# V32F20x_CM33 register map
File version: 1.0.3
CPU: CM33 r0p4, little endian, MPU, FPU, DSP, 3 interrupt priority bits, 8 SAU regions
Registers are 32-bit, read-write, reset 0x0 unless marked. A register's access mark holds for its fields unless they carry their own. Offsets are from the block's base; [hi:lo] are bit positions; {n}, {i} and the like mark numbered series; 'fields as' and 'values as' point back to an identical list.

## SCR — SCR Peripheral Interface
Base 0x40070000
Same registers: SEC_SCR 0x50070000
0x00 APB0PPC_SEC — APB0PPC security configuration register.
  [31:0] SEC — This register is used to control secure access mode for each module
0x04 APB0PPC_AP — APB0PPC access privilege configuration register.
  [31:0] AP — This register is used to control privilege access mode for each module
0x08 APB0PPC_RESP — APB0PPC security violation response configuration register
  [0] RESP — APBPPC in CM33 system security violation response configuration
0x0C APB0PPC_SEC1 — APB0PPC security configuration 1 register.
  fields as APB0PPC_SEC
0x10 APB0PPC_AP1 — APB0PPC access privilege configuration 1 register.
  fields as APB0PPC_AP
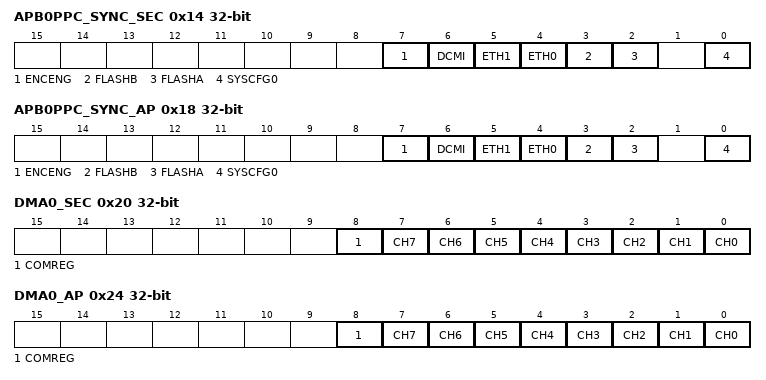
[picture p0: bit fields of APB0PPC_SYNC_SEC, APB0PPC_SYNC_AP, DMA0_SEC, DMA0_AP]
0x14 APB0PPC_SYNC_SEC — APB0PPC_SYNC security configuration register.
  [7] ENCENG — Secure access mode for ENCENG.
  [6] DCMI — Secure access mode for DCMI.
  [5] ETH1 — Secure access mode for ETH1.
  [4] ETH0 — Secure access mode for ETH0.
  [3] FLASHB — Secure access mode for FLASHB controller.
  [2] FLASHA — Secure access mode for FLASHA controller.
  [0] SYSCFG0 — Secure access mode for SYSCFG0.
0x18 APB0PPC_SYNC_AP — APB0PPC_SYNC access privilege configuration register
  [7] ENCENG — Privilege access mode for ENCENG.
  [6] DCMI — Privilege access mode for DCMI.
  [5] ETH1 — Privilege access mode for ETH1.
  [4] ETH0 — Privilege access mode for ETH0.
  [3] FLASHB — Privilege access mode for FLASHB controller.
  [2] FLASHA — Privilege access mode for FLASHA controller.
  [0] SYSCFG0 — Privilege access mode for SYSCFG0.
0x1C APB0PPC_SYNC_RESP — APB0PPC_SYNC security violation response configuration register
  [0] RESP — Sync APBPPC in CM33 system security violation response configuration
0x20 DMA0_SEC — DMA0 security configuration register.
  [8] COMREG — DMA0 common registers security configuration:
  [n] CH{n} (n=0..7) — DMA0 channel {n} security configuration:
0x24 DMA0_AP — DMA0 access privilege configuration register.
  [8] COMREG — DMA0 common registers privilege access configuration
  [n] CH{n} (n=0..7) — DMA0 channel {n} privilege access configuration:
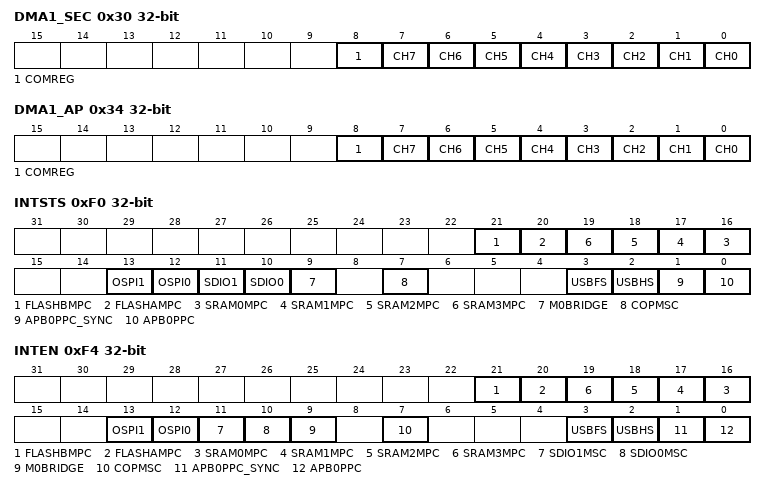
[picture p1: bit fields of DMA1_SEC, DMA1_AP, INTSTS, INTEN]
0x30 DMA1_SEC — DMA1 security configuration register.
  [8] COMREG — DMA1 common registers security configuration:
  [n] CH{n} (n=0..7) — DMA1 channel {n} security configuration:
0x34 DMA1_AP — DMA1 access privilege configuration register.
  [8] COMREG — DMA1 common registers privilege access configuration
  [n] CH{n} (n=0..7) — DMA1 channel {n} privilege access configuration:
0x40 ETH0_SEC — ETH0 security configuration register.
  [0] MSC — ETH0 master security configuration
0x44 ETH0_AP — ETH0 access privilege configuration register.
  [0] MSC — ETH0 master privilege access configuration:
0x50 ETH1_SEC — ETH1 security configuration register.
  [0] MSC — ETH1 master security configuration
0x54 ETH1_AP — ETH1 access privilege configuration register.
  [0] MSC — ETH0 master privilege access configuration:
0x60 ENCENG_SEC — ENCENG security configuration register.
  [0] MSC — ENCENG master security configuration
0x64 ENCENG_AP — ENCENG access privilege configuration register.
  [0] MSC — ENCENG master privilege access configuration:
0x80 SDIO0_SEC — SDIO0 security configuration register.
  [0] MSC — SDIO0 master security configuration
0x84 SDIO0_AP — SDIO0 access privilege configuration register.
  [0] MSC — SDIO0 master privilege access configuration:
0x90 SDIO1_SEC — SDIO1 security configuration register.
  [0] MSC — SDIO1 master security configuration
0x94 SDIO1_AP — SDIO1 access privilege configuration register.
  [0] MSC — SDIO1 master privilege access configuration:
0xA0 OSPI0_SEC — OSPI0 security configuration register.
  [16] SEC — OSPI0 security configuration:
0xA4 OSPI0_AP — OSPI0 access privilege configuration register.
  [16] AP — OSPI0 privilege access configuration:
0xA8 OSPI0_RESP — OSPI0 security violation response configuration register
  [16] RESP — OSPI0 security violation response configuration:
0xB0 OSPI1_SEC wo — OSPI1 security configuration register.
  [16] SEC — OSPI1 security configuration:
0xB4 OSPI1_AP — OSPI1 access privilege configuration register.
  [16] AP — OSPI1 privilege access configuration:
0xB8 OSPI1_RESP — OSPI1 security violation response configuration register
  [16] RESP — OSPI1 security violation response configuration:
0xC0 M0BRIDGE_SEC — M0BRIDGE security configuration register.
  [16] SEC — AHB2AHB Bridge security configuration:
0xC4 M0BRIDGE_AP — M0BRIDGE access privilege configuration register.
  [16] AP — AHB2AHB Bridge privilege access configuration:
0xC8 M0BRIDGE_RESP — M0BRIDGE security violation response configuration register
  [16] RESP — AHB2AHB Bridge security violation response configuration
0xD0 USBHS_SEC — USB_HS security configuration register.
  [16] SEC — USB_HS Bridge security configuration:
0xD4 USBHS_AP — USB_HS access privilege configuration register.
  [16] AP — USB_HS privilege access configuration:
0xD8 USBHS_RESP — USB_HS security violation response configuration register
  [16] RESP — USB_HS security violation response configuration:
0xE0 USBFS_SEC — USB_FS security configuration register.
  [16] SEC — USB_FS Bridge security configuration:
0xE4 USBFS_AP — USB_FS access privilege configuration register.
  [16] AP — USB_FS privilege access configuration:
0xE8 USBFS_RESP — USB_FS security violation response configuration register
  [16] RESP — USB_FS security violation response configuration:
0xF0 INTSTS — Security violation interrupt status register.
  [21] FLASHBMPC — Flash B MPC security violation interrupt status.
  [20] FLASHAMPC — Flash A MPC security violation interrupt status.
  [n+16] SRAM{n}MPC (n=0..3) — SRAM{n} MPC security violation interrupt status.
  [13] OSPI1 — OSPI1 security violation interrupt status.
  [12] OSPI0 — OSPI0 security violation interrupt status.
  [11] SDIO1 — SDIO0 security violation interrupt status.
  [10] SDIO0 — SDIO1 security violation interrupt status.
  [9] M0BRIDGE — AHB2AHB bridge security violation interrupt status
  [7] COPMSC — COP master security violation interrupt status.
  [3] USBFS — USBFS security violation interrupt status.
  [2] USBHS — USBHS security violation interrupt status.
  [1] APB0PPC_SYNC — APB0PPC_SYNC security violation interrupt status.
  [0] APB0PPC — APB0PPC security violation interrupt status.
0xF4 INTEN — Security violation interrupt enable register.
  [21] FLASHBMPC — Flash B MPC security violation interrupt enable.
  [20] FLASHAMPC — Flash A MPC security violation interrupt enable.
  [n+16] SRAM{n}MPC (n=0..3) — SRAM{n} MPC security violation interrupt enable.
  [13] OSPI1 — OSPI1 security violation interrupt enable.
  [12] OSPI0 — OSPI0 security violation interrupt enable.
  [11] SDIO1MSC — SDIO1 MSC security violation interrupt enable.
  [10] SDIO0MSC — SDIO0 MSC security violation interrupt enable.
  [9] M0BRIDGE — AHB2AHB bridge security violation interrupt enable
  [7] COPMSC — COP MSC security violation interrupt enable.
  [3] USBFS — USBFS security violation interrupt enable.
  [2] USBHS — USBHS security violation interrupt enable.
  [1] APB0PPC_SYNC — APB0PPC_SYNC security violation interrupt enable.
  [0] APB0PPC — APB0PPC security violation interrupt enable.
0xF8 BUSY ro — Security configuration busy state register.
  [0] BUSY — The status of SCR configuration:
